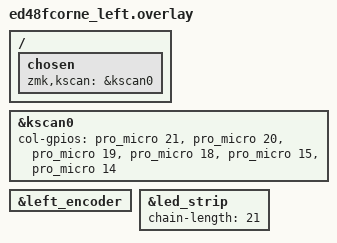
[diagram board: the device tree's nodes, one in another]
/*
 * Copyright (c) 2020 Pete Johanson
 *
 * SPDX-License-Identifier: MIT
 */

#include "ed48fcorne.dtsi"

&kscan0 {
    col-gpios
        = <&pro_micro 21 GPIO_ACTIVE_HIGH>
        , <&pro_micro 20 GPIO_ACTIVE_HIGH>
        , <&pro_micro 19 GPIO_ACTIVE_HIGH>
        , <&pro_micro 18 GPIO_ACTIVE_HIGH>
        , <&pro_micro 15 GPIO_ACTIVE_HIGH>
        , <&pro_micro 14 GPIO_ACTIVE_HIGH>
        ;
        
};

/ {
    chosen {
        zmk,kscan = &kscan0;
    };
};

&left_encoder {
    status = "okay";
};

&led_strip {
    chain-length = <21>;
};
